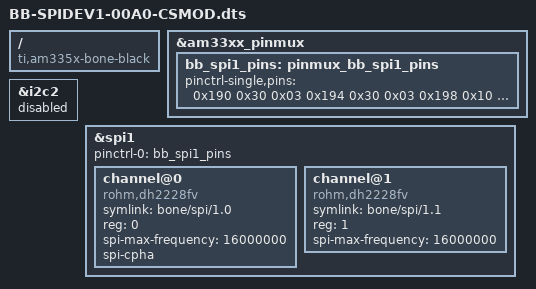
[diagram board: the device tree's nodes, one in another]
/dts-v1/;
/plugin/;

/ {
	compatible = "ti,am335x-bone-black", "ti,am335x-bone", "ti,am33xx";

	fragment@0 {
		target = <&am33xx_pinmux>;
		__overlay__ {
			bb_spi1_pins: pinmux_bb_spi1_pins {
				pinctrl-single,pins = <
					0x190 0x30 0x03   /* P9_31 mcasp0_aclkx.spi1_sclk, INPUT_PULLUP | MODE3 */
					0x194 0x30 0x03   /* P9_29 mcasp0_fsx.spi1_d0,     INPUT_PULLUP | MODE3 */
					0x198 0x10 0x03   /* P9_30 mcasp0_axr0.spi1_d1,    OUTPUT_PULLUP | MODE3 */
					0x178 0x10 0x04   /* P9_19 uart1_ctsn.spi1_cs1,    OUTPUT_PULLUP | MODE4 */
					0x17c 0x10 0x04   /* P9_20 uart1_rtsn.spi1_cs0,    OUTPUT_PULLUP | MODE4 */
				>;
			};
		};
	};

	/* Free P9.19/P9.20 from the default cape-EEPROM I2C2 bus so SPI1 can own them */
	fragment@1 {
		target = <&i2c2>;
		__overlay__ {
			status = "disabled";
		};
	};

	fragment@2 {
		target = <&spi1>;
		__overlay__ {
			#address-cells = <1>;
			#size-cells = <0>;
			status = "okay";
			pinctrl-names = "default";
			pinctrl-0 = <&bb_spi1_pins>;

			channel@0 {
				#address-cells = <1>;
				#size-cells = <0>;
				compatible = "rohm,dh2228fv";
				symlink = "bone/spi/1.0";
				reg = <0>;
				spi-max-frequency = <16000000>;
				spi-cpha;
			};

			channel@1 {
				#address-cells = <1>;
				#size-cells = <0>;
				compatible = "rohm,dh2228fv";
				symlink = "bone/spi/1.1";
				reg = <1>;
				spi-max-frequency = <16000000>;
			};
		};
	};
};
